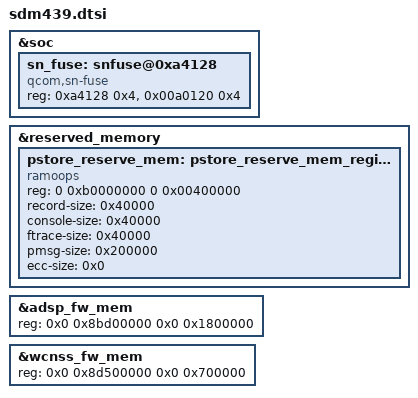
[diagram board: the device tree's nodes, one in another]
&soc {
	sn_fuse: snfuse@0xa4128 {
		compatible = "qcom,sn-fuse";
		reg = <0xa4128 0x4>,
		      <0x00a0120 0x4>;
		reg-names = "sn-base","cfi-base";
	};
};

&reserved_memory {
	pstore_reserve_mem: pstore_reserve_mem_region@0 {
		compatible = "ramoops";
		reg = <0 0xb0000000 0 0x00400000>;
		record-size = <0x40000>;
		console-size = <0x40000>;
		ftrace-size = <0x40000>;
		pmsg-size = <0x200000>;
		ecc-size = <0x0>;
	};
};

&adsp_fw_mem {
	reg = <0x0 0x8bd00000 0x0 0x1800000>;
};

&wcnss_fw_mem {
	reg = <0x0 0x8d500000 0x0 0x700000>;
};
